# PRU_ICSS_0_MII_RT_local register map
Vendor: Texas Instruments
Peripheral module from a debugger description file (folder 66AK2G0x_66AK2G1x).
Registers are 32-bit, access per field, reset 0x0 unless marked. A register's access mark holds for its fields unless they carry their own. Offsets are as the file gives them; lines under a group give offsets from that group; [hi:lo] are bit positions; {n}, {i} and the like mark numbered series; 'fields as' and 'values as' point back to an identical list; <NAME> marks a mode.

## PRU_ICSS_0_MII_RT
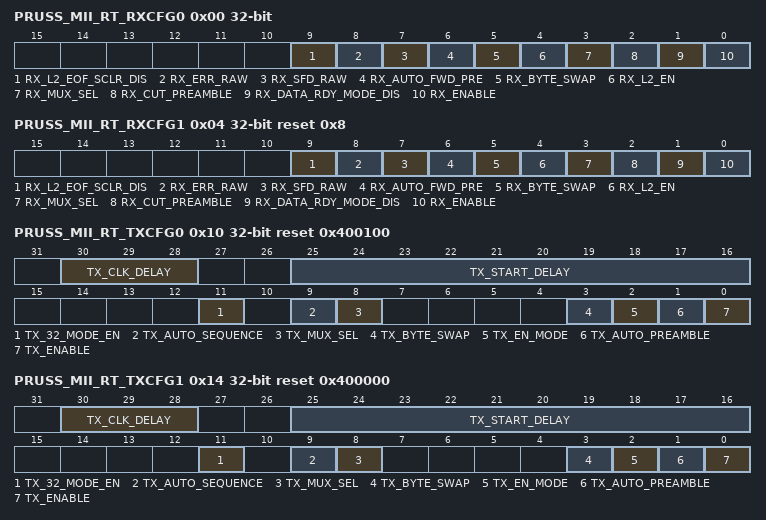
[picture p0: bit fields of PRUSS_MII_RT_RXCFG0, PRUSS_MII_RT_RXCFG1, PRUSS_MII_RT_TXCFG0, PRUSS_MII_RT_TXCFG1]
0x00 PRUSS_MII_RT_RXCFG0
  [9] RX_L2_EOF_SCLR_DIS rw — 0h: RX_EOF flag in R31 and RXL2 is self cleared by hardware when RXL2 is enabled
  [8] RX_ERR_RAW rw — 0h: Error Raw Mode Disabled. RX_ERR is qualified with RX_DV, meaning RX_DV = 1 before RX_ERR action/event is generated.
  [7] RX_SFD_RAW rw — 0h: SFD Raw Mode Disabled. RX_SFD requires a pattern of 5D.
  [6] RX_AUTO_FWD_PRE rw — Enables auto-forward of received preamble. When enabled, this will forward the preamble nibbles including the SFD to the TX L1 FIFO that is attached to the PRU. First data byte seen by PRU R31 and/or RX L2 is destination address (DA). Note: Odd number of preamble nibbles is supported in this mode. For example, 0x55D Note that new RX should only occur after the current TX completes 0h: Disable 1h: Enable, it must disable RX_CUT_PREAMBLE and TX_AUTO_PREAMBLE
  [5] RX_BYTE_SWAP rw — Defines the order of Byte0/1 placement for RX R31 and RX L2. Note: that if TX_AUTO_SEQUENCE enabled, this bit cannot get enable since TX_BYTE_SWAP on swaps the PRU output. This bit must be selected/updated when the port is disabled or there is no traffic. 0h: R31 [15:8]/RXL2 [15:8] = Byte1{Nibble3,Nibble2} R31[ 7:0]/RXL2 [7:0] = Byte0{Nibble1,Nibble0} 1h: R31 [15:8]/RXL2 [15:8] = Byte0{Nibble1,Nibble0} R31[ 7:0]/RXL2 [7:0] = Byte1{Nibble3,Nibble2} Nibble0 is the first nibble received.
  [4] RX_L2_EN rw — Enables RX L2 buffer. 0h: Disable (RX L2 can function as generic scratch pad) 1h: Enable
  [3] RX_MUX_SEL rw — Selects receive data source. Typically, the setting for this will not be identical for the two MII receive configuration registers. 0h: MII RX Data from Port 0 (default for PRUSS_MII_RT_RXCFG0) 1h: MII RX Data from Port 1 (default for PRUSS_MII_RT_RXCFG1)
  [2] RX_CUT_PREAMBLE rw — Removes received preamble. 0h: All data from Ethernet PHY are passed on to PRU register. This assumes Ethernet PHY which does not shorten the preamble. 1h: MII interface suppresses preamble and sync frame delimiter. First data byte seen by PRU register is destination address.
  [1] RX_DATA_RDY_MODE_DIS rw — 0h: R31, Bit 16 is configured for DATA_RDY mode. 1h: R31, Bit 16 is configured for TX_EOF mode.
  [0] RX_ENABLE rw — Enables the receive traffic currently selected by RX_MUX_SELECT. 0h: Disable 1h: Enable
0x04 PRUSS_MII_RT_RXCFG1 reset 0x8
  [9] RX_L2_EOF_SCLR_DIS rw — 0h: RX_EOF flag in R31 and RXL2 is self cleared by hardware when RXL2 is enabled
  [8] RX_ERR_RAW rw — 0h: Error Raw Mode Disabled. RX_ERR is qualified with RX_DV, meaning RX_DV = 1 before RX_ERR action/event is generated.
  [7] RX_SFD_RAW rw — 0h: SFD Raw Mode Disabled. RX_SFD requires a pattern of 5D.
  [6] RX_AUTO_FWD_PRE rw — Enables auto-forward of received preamble.
  [5] RX_BYTE_SWAP rw — Defines the order of Byte0/1 placement for RX R31 and RX L2.
  [4] RX_L2_EN rw — Enables RX L2 buffer.
  [3] RX_MUX_SEL rw — Selects receive data source. Typically, the setting for this will not be identical for the two MII receive configuration registers.
  [2] RX_CUT_PREAMBLE rw — Removes received preamble.
  [1] RX_DATA_RDY_MODE_DIS rw — 0h: R31, Bit 16 is configured for DATA_RDY mode.
  [0] RX_ENABLE rw — Enables the receive traffic currently selected by RX_MUX_SELECT.
0x10 PRUSS_MII_RT_TXCFG0 reset 0x400100
  [30:28] TX_CLK_DELAY rw — In order to guarantee the MII_RT IO timing values published in the device data manual, the ICSS_i_VCLK_CLK (where i = 0 or 1) clock must be configured for 200MHz and TX_CLK_DELAY must be set to 6h.
  [25:16] TX_START_DELAY rw — Defines the minimum time interval (delay) between receiving the RXDV for the current frame and the start of the transmit interface sending data to the MII interface.
  [11] TX_32_MODE_EN rw — 0h: Disable 32-bit Data Push mode.
  [9] TX_AUTO_SEQUENCE rw — Enables transmit auto-sequence. Note the transmit data source is determined by TX_MUX_SEL setting.
  [8] TX_MUX_SEL rw — Selects transmit data source.
  [3] TX_BYTE_SWAP rw — Defines the order of Byte0/1 placement for TX R30. This bit must be selected/updated when the port is disabled or there is no traffic.
  [2] TX_EN_MODE rw — Enables transmit self clear on TX_EOF event.
  [1] TX_AUTO_PREAMBLE rw — Transmit data auto-preamble.
  [0] TX_ENABLE rw — Enables transmit traffic on TX PORT.
0x14 PRUSS_MII_RT_TXCFG1 reset 0x400000
  fields as PRUSS_MII_RT_TXCFG0
0x20 PRUSS_MII_RT_TX_CRC0 ro
  [31:0] TX_CRC — FCS (CRC32) data can be read by PRU for diagnostics. It is only valid after 6 clocks after a TX_CRC_HIGH command is given.
0x24 PRUSS_MII_RT_TX_CRC1 ro
  fields as PRUSS_MII_RT_TX_CRC0
0x30 PRUSS_MII_RT_TX_IPG0 reset 0x28
  [9:0] TX_IPG rw — Defines the minimum of transmit Inter Packet Gap (IPG) which is the number of ICSS_i_VCLK_CLK (where i = 0 or 1) cycles between the de-assertion of TX_EN and the assertion of TX_EN.
0x34 PRUSS_MII_RT_TX_IPG1 reset 0x28
  [9:0] TX_IPG rw — Defines the minimum of transmit Inter Packet Gap (IPG) which is the number of ICSS_i_VCLK_CLK (where i = 0 or 1) cycles between the de-assertion of TX_EN and the assertion of TX_EN. The start of the TX will get delayed when the incoming packet IPG is less than defined minimum value. In general, software should program in increments of 8, 40ns to insure the extra delays takes effect.
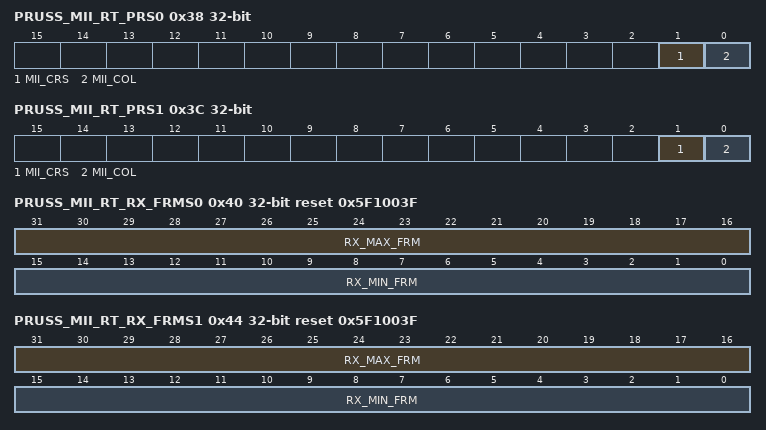
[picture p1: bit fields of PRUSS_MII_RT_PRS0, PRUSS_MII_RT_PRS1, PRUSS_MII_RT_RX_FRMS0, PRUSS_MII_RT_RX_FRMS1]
0x38 PRUSS_MII_RT_PRS0 ro
  [1] MII_CRS — Read the current state of pr1_mii0_crs
  [0] MII_COL — Read the current state of pr1_mii0_col
0x3C PRUSS_MII_RT_PRS1 ro
  [1] MII_CRS — Read the current state of pr1_mii1_crs
  [0] MII_COL — Read the current state of pr1_mii1_col
0x40 PRUSS_MII_RT_RX_FRMS0 rw reset 0x5F1003F
  [31:16] RX_MAX_FRM — Defines the maximum received frame count. Note if the incoming frame is truncated at the marker, RX_CRC and RX_NIBBLE_ODD will not get asserted.
  [15:0] RX_MIN_FRM — Defines the minimum received frame count.
0x44 PRUSS_MII_RT_RX_FRMS1 rw reset 0x5F1003F
  [31:16] RX_MAX_FRM — Defines the maximum received frame count. If the total byte count of the received frame is more than defined value, RX_MAX_FRM_ERR will get set.
  [15:0] RX_MIN_FRM — Defines the minimum received frame count.
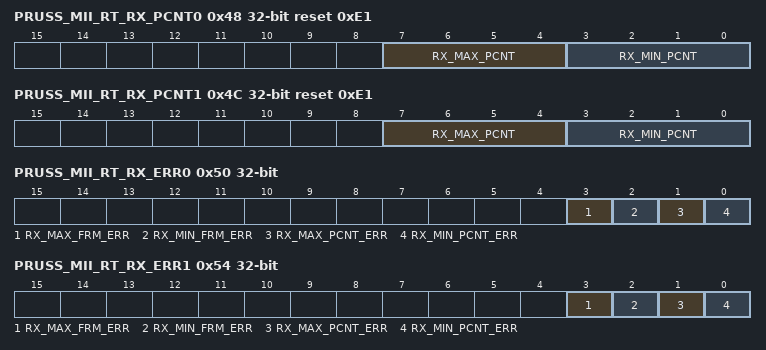
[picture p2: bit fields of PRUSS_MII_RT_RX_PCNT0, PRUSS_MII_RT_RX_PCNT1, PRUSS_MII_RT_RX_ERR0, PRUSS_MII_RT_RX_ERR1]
0x48 PRUSS_MII_RT_RX_PCNT0 reset 0xE1
  [7:4] RX_MAX_PCNT rw — Defines the maximum number of nibbles until the start of frame delimiter (SFD) event occurred (i.e. matches 0xD5).
  [3:0] RX_MIN_PCNT rw — Defines the minimum number of nibbles until the start of frame delimiter (SFD) event occurred, which is matched the value 0xD5.
0x4C PRUSS_MII_RT_RX_PCNT1 reset 0xE1
  fields as PRUSS_MII_RT_RX_PCNT0
0x50 PRUSS_MII_RT_RX_ERR0 access not given
  [3] RX_MAX_FRM_ERR — Error status of received frame is more than the value of RX_MAX_FRM. (access RWr1Clr)
  [2] RX_MIN_FRM_ERR — Error status of received frame is less than the value of RX_MIN_FRM. (access RWr1Clr)
  [1] RX_MAX_PCNT_ERR — Error status of received preamble nibble is more than the value of RX_MAX_PCNT. (access RWr1Clr)
  [0] RX_MIN_PCNT_ERR — Error status of received preamble nibble is less than the value of RX_MIN_PCNT. (access RWr1Clr)
0x54 PRUSS_MII_RT_RX_ERR1 access not given
  [3] RX_MAX_FRM_ERR — Error status of received frame is more than the value of RX_MAX_FRM_CNT. (access RWr1Clr)
  [2] RX_MIN_FRM_ERR — Error status of received frame is less than the value of RX_MIN_FRM_CNT. (access RWr1Clr)
  [1] RX_MAX_PCNT_ERR — Error status of received preamble nibble is more than the value of RX_MAX_PCNT. (access RWr1Clr)
  [0] RX_MIN_PCNT_ERR — Error status of received preamble nibble is less than the value of RX_MIN_PCNT. (access RWr1Clr)
0x60 PRUSS_MII_RT_RXFLV0 access not given
  [7:0] RX_FIFO_LEVEL — Define the number of valid bytes in the RX FIFO. (access RWr1Clr)
0x64 PRUSS_MII_RT_RXFLV1 access not given
  fields as PRUSS_MII_RT_RXFLV0
0x68 PRUSS_MII_RT_TXFLV0 access not given
  [7:0] TX_FIFO_LEVEL — Define the number of valid nibbles in the TX FIFO. (access RWr1Clr)
0x6C PRUSS_MII_RT_TXFLV1 access not given
  fields as PRUSS_MII_RT_TXFLV0
